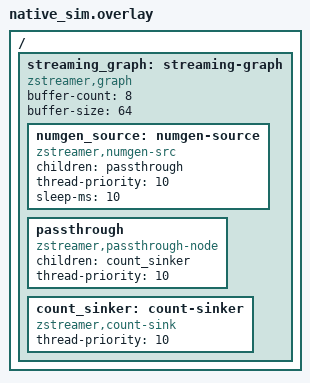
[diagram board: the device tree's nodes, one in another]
/*
 * Copyright (c) 2026 sharonthecreator
 * SPDX-License-Identifier: Apache-2.0
 */

/ {
	streaming_graph: streaming-graph {
		compatible = "zstreamer,graph";
		buffer-count = <8>;
		buffer-size = <64>;

		numgen_source: numgen-source {
			compatible = "zstreamer,numgen-src";
			children = <&passthrough>;
			thread-priority = <10>;
			sleep-ms = <10>;
		};

		passthrough: passthrough {
			compatible = "zstreamer,passthrough-node";
			children = <&count_sinker>;
			thread-priority = <10>;
		};

		count_sinker: count-sinker {
			compatible = "zstreamer,count-sink";
			thread-priority = <10>;
		};
	};
};
